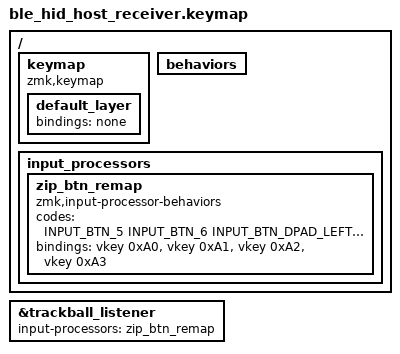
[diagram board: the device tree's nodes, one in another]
/*
 * zmk-mouse keymap -- dedicated USB trackball dongle (XIAO nRF52840).
 *
 * The dongle has no physical keys, so the keymap is a single no-op binding.
 * Mouse motion comes from the zmk,ble-hid-host device (BLE central to the
 * trackball, from the akira-toriyama/zmk-ble-hid-host module) and is fed into
 * ZMK via &trackball_listener (defined in the receiver shield's overlay).
 *
 * ===========================  CUSTOMIZE HERE (M4)  ==========================
 * Attach input-processors to &trackball_listener. Uncomment + adapt:
 *
 *   // Remap mouse button 4 -> key 'a'. First confirm the REAL code: flash the
 *   // -logging .uf2 and watch `buttons=0x..`; ble_hid_host_publish emits
 *   // INPUT_BTN_0 + i, so button 4 is usually INPUT_BTN_3.
 *   #include <zephyr/dt-bindings/input/input-event-codes.h>
 *
 *   / {
 *       input_processors {
 *           zip_btn4_to_a: zip_btn4_to_a {
 *               compatible = "zmk,input-processor-behaviors";
 *               #input-processor-cells = <0>;     // REQUIRED
 *               codes    = <INPUT_BTN_3>;          // codes.length == bindings.length
 *               bindings = <&kp A>;
 *           };
 *       };
 *   };
 *
 *   &trackball_listener {
 *       input-processors = <&zip_btn4_to_a>;
 *   };
 *
 * Axis invert / swap / scale / snipe / scroll are stock processors you attach
 * the same way -- see https://zmk.dev/docs/keymaps/input-processors .
 * ===========================================================================
 */

#include <behaviors.dtsi>
#include <dt-bindings/zmk/keys.h>
#include <zephyr/dt-bindings/input/input-event-codes.h>   /* INPUT_BTN_5/6, DPAD_* */

/ {
    keymap {
        compatible = "zmk,keymap";

        default_layer {
            bindings = <&none>;
        };
    };

    behaviors {
        // 共有 &vkey behavior（imprint.keymap と同一の唯一ソース）。
        #include "vkey_behavior.dtsi"
    };

    /* Extra mouse buttons + horizontal tilt -> vkey (Elecom IST PRO).
     *
     * Each button/tilt fires a vendor-HID "original key" (&vkey, Report ID
     * 0x20) that the macOS host bridge (chord) maps to an action — instead of a
     * literal keycode. id band 0xA0..0xBF is reserved for ist and kept disjoint
     * from imprint's vkey ids; scripts/gen-vkey-aliases.py derives the chord
     * aliases (IST_BTN5/BTN6/TILT_L/TILT_R) from the codes<->bindings pairing.
     *
     * Buttons: INPUT_BTN_5 (bit5, 0x0020) / INPUT_BTN_6 (bit6, 0x0040) are only
     * emitted when the zmk-ble-hid-host module publishes >5 buttons
     * (BLE_HID_HOST_PUBLISH_BTNS >= 8 on main).
     *
     * Tilt: INPUT_BTN_DPAD_LEFT/RIGHT are synthetic taps the module emits per
     * horizontal-wheel (tilt) tick when CONFIG_ZMK_BLE_HID_HOST_HWHEEL_AS_KEYS
     * is set in ble_hid_host_receiver.conf. The vertical wheel is left as normal
     * scroll (WHEEL_AS_KEYS off), so no DPAD_UP/DOWN here.
     *
     * codes.length must equal bindings.length. */
    input_processors {
        zip_btn_remap: zip_btn_remap {
            compatible = "zmk,input-processor-behaviors";
            #input-processor-cells = <0>;          /* REQUIRED */
            codes = <INPUT_BTN_5 INPUT_BTN_6
                     INPUT_BTN_DPAD_LEFT INPUT_BTN_DPAD_RIGHT>;
            bindings = <&vkey 0xA0 &vkey 0xA1
                        &vkey 0xA2 &vkey 0xA3>;    /* BTN5/BTN6, tilt L/R -> chord */
        };
    };
};

&trackball_listener {
    input-processors = <&zip_btn_remap>;
};
